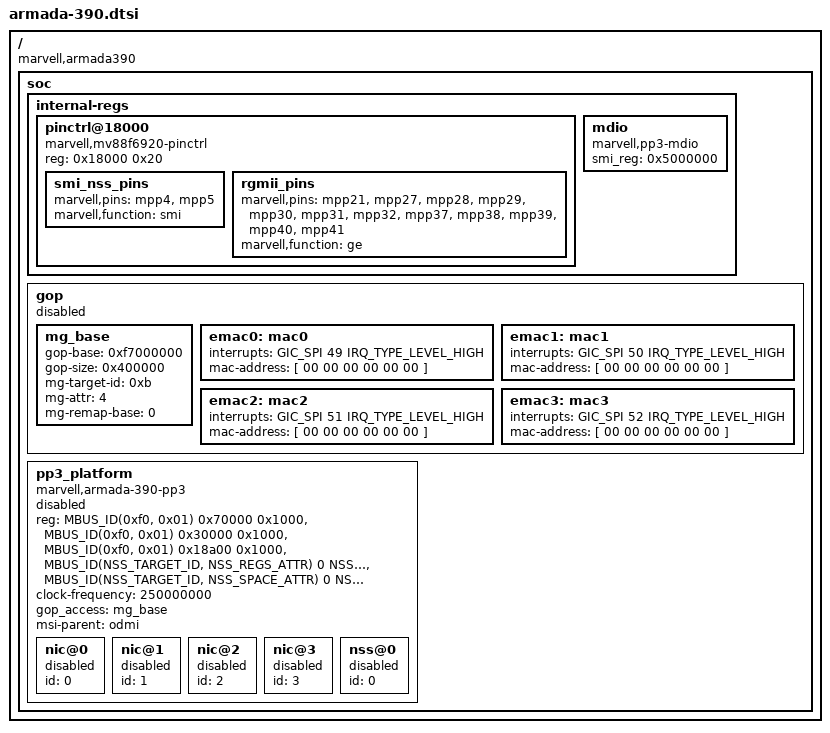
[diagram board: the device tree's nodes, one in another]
/*
 * Device Tree Include file for Marvell Armada 390 SoC.
 *
 * Copyright (C) 2015 Marvell
 *
 * Thomas Petazzoni <thomas.petazzoni@free-electrons.com>
 *
 * This file is dual-licensed: you can use it either under the terms
 * of the GPL or the X11 license, at your option. Note that this dual
 * licensing only applies to this file, and not this project as a
 * whole.
 *
 *  a) This file is free software; you can redistribute it and/or
 *     modify it under the terms of the GNU General Public License as
 *     published by the Free Software Foundation; either version 2 of the
 *     License, or (at your option) any later version.
 *
 *     This file is distributed in the hope that it will be useful
 *     but WITHOUT ANY WARRANTY; without even the implied warranty of
 *     MERCHANTABILITY or FITNESS FOR A PARTICULAR PURPOSE.  See the
 *     GNU General Public License for more details.
 *
 * Or, alternatively
 *
 *  b) Permission is hereby granted, free of charge, to any person
 *     obtaining a copy of this software and associated documentation
 *     files (the "Software"), to deal in the Software without
 *     restriction, including without limitation the rights to use
 *     copy, modify, merge, publish, distribute, sublicense, and/or
 *     sell copies of the Software, and to permit persons to whom the
 *     Software is furnished to do so, subject to the following
 *     conditions:
 *
 *     The above copyright notice and this permission notice shall be
 *     included in all copies or substantial portions of the Software.
 *
 *     THE SOFTWARE IS PROVIDED , WITHOUT WARRANTY OF ANY KIND
 *     EXPRESS OR IMPLIED, INCLUDING BUT NOT LIMITED TO THE WARRANTIES
 *     OF MERCHANTABILITY, FITNESS FOR A PARTICULAR PURPOSE AND
 *     NONINFRINGEMENT. IN NO EVENT SHALL THE AUTHORS OR COPYRIGHT
 *     HOLDERS BE LIABLE FOR ANY CLAIM, DAMAGES OR OTHER LIABILITY
 *     WHETHER IN AN ACTION OF CONTRACT, TORT OR OTHERWISE, ARISING
 *     FROM, OUT OF OR IN CONNECTION WITH THE SOFTWARE OR THE USE OR
 *     OTHER DEALINGS IN THE SOFTWARE.
 */

#include "armada-39x.dtsi"
#include <dt-bindings/mvebu_nss/nss39x.h>

/ {
	compatible = "marvell,armada390";

	soc {
		internal-regs {
			pinctrl@18000 {
				compatible = "marvell,mv88f6920-pinctrl";
				reg = <0x18000 0x20>;
				smi_nss_pins: smi_nss_pins {
					marvell,pins = "mpp4", "mpp5";
					marvell,function = "smi";
				};
				rgmii_pins: rgmii_pins {
					marvell,pins = "mpp21", "mpp27", "mpp28",
							"mpp29", "mpp30", "mpp31",
							"mpp32", "mpp37", "mpp38",
							"mpp39", "mpp40", "mpp41";
					marvell,function = "ge";
				};
			};
			mdio {
				#address-cells = <1>;
				#size-cells = <0>;
				compatible = "marvell,pp3-mdio";
				smi_reg = <0x5000000>;
			};
		};

		gop {
			status = "disabled";
			mg_base: mg_base {
				gop-base = <0xf7000000>;
				gop-size = <0x400000>;
				mg-target-id = <0xb>;
				mg-attr = <4>;
				mg-remap-base = <0>;
			};

			emac0: mac0 {
				interrupts = <GIC_SPI 49 IRQ_TYPE_LEVEL_HIGH>;  /* Link IRQ */
				mac-address = [ 00 00 00 00 00 00 ];
			};

			emac1: mac1 {
				interrupts = <GIC_SPI 50 IRQ_TYPE_LEVEL_HIGH>;  /* Link IRQ */
				mac-address = [ 00 00 00 00 00 00 ];
			};

			emac2: mac2 {
				interrupts = <GIC_SPI 51 IRQ_TYPE_LEVEL_HIGH>;  /* Link IRQ */
				mac-address = [ 00 00 00 00 00 00 ];
			};
			emac3: mac3 {
				interrupts = <GIC_SPI 52 IRQ_TYPE_LEVEL_HIGH>;  /* Link IRQ */
				mac-address = [ 00 00 00 00 00 00 ];
			};
		};

		pp3_platform {
			compatible = "marvell,armada-390-pp3";
			status = "disabled";
			reg = <MBUS_ID(0xf0, 0x01) 0x70000 0x1000>,    /* A2M Master 0 */
			      <MBUS_ID(0xf0, 0x01) 0x30000 0x1000>,    /* A2M Master 1 */
			      <MBUS_ID(0xf0, 0x01) 0x18a00 0x1000>,    /* AMB registers */
			      <MBUS_ID(NSS_TARGET_ID, NSS_REGS_ATTR)  0 NSS_REGS_SIZE>, /* NSS IP registers */
			      <MBUS_ID(NSS_TARGET_ID, NSS_SPACE_ATTR) 0 NSS_SPACE_SIZE>; /* NSS IP space */
			clock-frequency = <250000000>;
			gop_access = <&mg_base>;
			msi-parent = <&odmi>;

			nic@0 {
				status = "disabled";
				id = <0>;
			};

			nic@1 {
				status = "disabled";
				id = <1>;
			};

			nic@2 {
				status = "disabled";
				id = <2>;
			};

			nic@3 {
				status = "disabled";
				id = <3>;
			};

			nss@0 {
				status = "disabled";
				id = <0>;
			};
		};
	};
};
